# CC2753 register map
File version: 1.0
CPU: CM0+ r0p4, little endian, no MPU, no FPU, VTOR, 3 interrupt priority bits
Registers are 32-bit, read-write, reset 0x0 unless marked. A register's access mark holds for its fields unless they carry their own. Offsets are from the block's base; [hi:lo] are bit positions; {n}, {i} and the like mark numbered series; 'fields as' and 'values as' point back to an identical list.

## HSMCRYPTO — HSM is a Root of Trust Engine that protects valuable assets, such as secret keys for embedded security sensitive applications in a Trusted Execution Environment
Base 0x400F0000
0x00 MB1IN ro — Input Mailbox 1
  [31:0] MEM — Input Mailbox Memory
0x00 MB1OUT wo — Output Mailbox 1
  [31:0] MEM — Output Mailbox Memory
0x400 MB2IN ro — Input Mailbox 2
  [31:0] MEM — Input Mailbox Memory
0x400 MB2OUT wo — Output Mailbox 2
  [31:0] MEM — Output Mailbox Memory
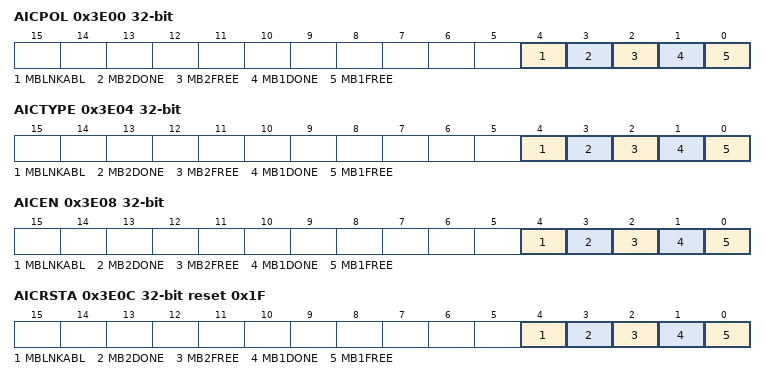
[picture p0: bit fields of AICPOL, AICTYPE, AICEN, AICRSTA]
0x3E00 AICPOL — AIC Polarity Control Register
  [all] fields
    1=HIGHRISE (High level/rising edge); 0=LOWFALL (Low level/falling edge)
  [4] MBLNKABL — Mailbox Linkable Interrupt Polarity
  [3] MB2DONE — Mailbox 2 Token Done Interrupt Polarity
  [2] MB2FREE — Mailbox 2 Free Interrupt Polarity
  [1] MB1DONE — Mailbox 1 Token done Interrupt Polarity
  [0] MB1FREE — Mailbox 1 Free Interrupt Polarity
0x3E04 AICTYPE — AIC Type Control Register
  [4] MBLNKABL — Mailbox Linkable Interrupt Type
    1=EDG (Edge); 0=LVL (Level)
  [3] MB2DONE — Mailbox 2 Token Done Interrupt Type
    1=EDG (Edge); 0=LEVEL
  [2] MB2FREE — Mailbox 2 Free Interrupt Type
    1=EDG (Edge); 0=LVL (Level)
  [1] MB1DONE — Mailbox 1 Token Done Interrupt Type
    1=EDG (Edge); 0=LVL (Level)
  [0] MB1FREE — Mailbox 1 Free Interrupt Type
    1=EDG (Edge); 0=LVL (Level)
0x3E08 AICEN — AIC Enable Control Register
  [all] fields
    1=EN (Enable); 0=DIS (Disable)
  [4] MBLNKABL — Mailbox Linkable Interrupt Enable. Indicates one or more mailbox can be linked
  [3] MB2DONE — Mailbox 2 Token Done Interrupt Enable
  [2] MB2FREE — Mailbox 2 Free Interrupt Enable
  [1] MB1DONE — Mailbox 1 Token done Interrupt Enable
  [0] MB1FREE — Mailbox 1 Free Interrupt Enable
0x3E0C AICRSTA ro reset 0x1F — AIC Raw Source Status Register
  [4] MBLNKABL — Mailbox Linkable Interrupt Status. Indicates one or more mailbox can be linked
  [3] MB2DONE — Mailbox 2 Token Done Interrupt Status
  [2] MB2FREE — Mailbox 2 Free Interrupt Status
  [1] MB1DONE — Mailbox 1 Token done Interrupt Status
  [0] MB1FREE — Mailbox 1 Free Interrupt Status
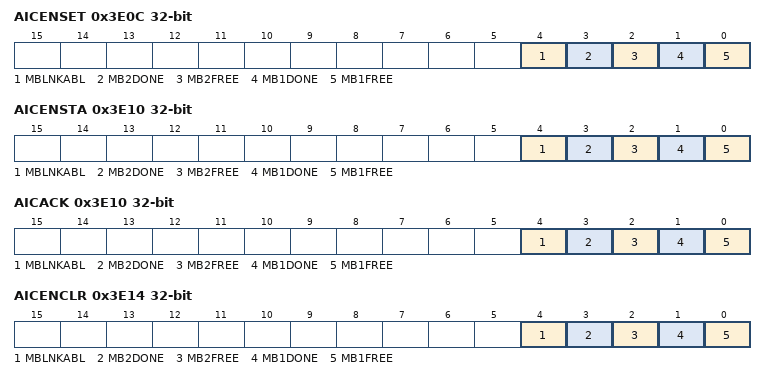
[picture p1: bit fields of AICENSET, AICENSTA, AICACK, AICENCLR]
0x3E0C AICENSET wo — AIC Enable Set Registers
  [all] fields
    1=SET (Set Enable)
  [4] MBLNKABL — Mailbox Linkable Interrupt Enable Set
  [3] MB2DONE — MailBox 2 Token Done Interrupt Enable Set
  [2] MB2FREE — MailBox 2 Free Interrupt Enable Set
  [1] MB1DONE — MailBox 1 Token Done Interrupt Enable Set
  [0] MB1FREE — MailBox 1 Free Interrupt Enable Set
0x3E10 AICENSTA ro — AIC Enabled Status Register
  [4] MBLNKABL — Mailbox Linkable Interrupt Enable Status
  [3] MB2DONE — Mailbox 2 Done Interrupt Enable Status
  [2] MB2FREE — MailBox 2 Free Interrupt Enable Status
  [1] MB1DONE — MailBox 1 Token Done Interrupt Enable Status
  [0] MB1FREE — Mailbox 1 Free Interrupt Enable Status
0x3E10 AICACK wo — AIC Acknowledge Register
  [all] fields
    1=ACK (Interrupt Ack)
  [4] MBLNKABL — Mailbox Linkable Interrupt Acknowledge
  [3] MB2DONE — Mailbox 2 Done Interrupt Acknowledge
  [2] MB2FREE — MailBox 2 Free Interrupt Acknowledge
  [1] MB1DONE — MailBox 1 Token Done Interrupt Acknowledge
  [0] MB1FREE — Mailbox 1 Free Interrupt Acknowledge
0x3E14 AICENCLR wo — AIC Enable Clear Register
  [all] fields
    1=CLR (Clear Enable)
  [4] MBLNKABL — Mailbox Linkable Interrupt Enable Clear
  [3] MB2DONE — Mailbox 2 Done Interrupt Enable Clear
  [2] MB2FREE — MailBox 2 Free Interrupt Enable Clear
  [1] MB1DONE — MailBox 1 Token Done Interrupt Enable Clear
  [0] MB1FREE — Mailbox 1 Free Interrupt Enable Clear
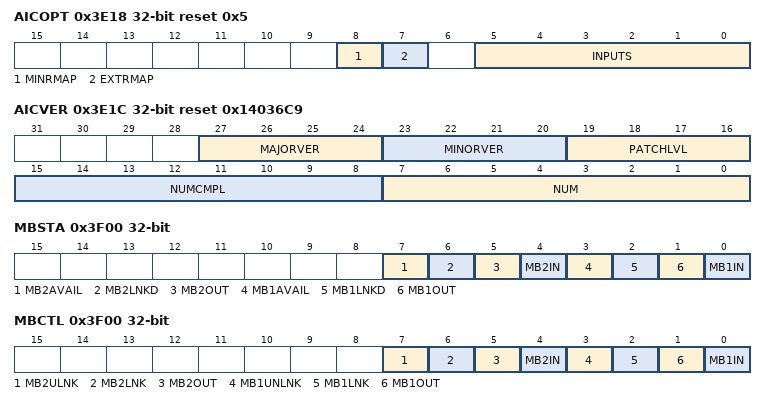
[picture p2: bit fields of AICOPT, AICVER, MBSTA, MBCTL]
0x3E18 AICOPT ro reset 0x5 — AIC Options Register
  [8] MINRMAP — Mini register map.
  [7] EXTRMAP — Extended register map.
  [5:0] INPUTS — The number of interrupt request inputs.
0x3E1C AICVER ro reset 0x14036C9 — AIC Version Register
  [27:24] MAJORVER — These bits encode the major version number for the AIC module.
  [23:20] MINORVER — These bits encode the minor version number for the AIC module.
  [19:16] PATCHLVL — These bits encode the hardware patch level for the AIC module, starting at value 0 on the first release.
  [15:8] NUMCMPL — These bits simply contain the complement of bits [7:0], used by a driver to ascertain that this version register is indeed read.
  [7:0] NUM — These bits encode the AIC number.
0x3F00 MBSTA ro — Mailbox Status Register
  [7] MB2AVAIL — Input Mailbox 2 available status
    1=AVAIL (Input Mailbox is available for linking by this Host); 0=NAVAIL (Input Mailbox is linked to a Host or is filled)
  [6] MB2LNKD — Mailbox 2 Link Status
    1=LNKD (This Host is linked to Mailbox); 0=NLNKD (This Host is not linked to Mailbox)
  [5] MB2OUT — Output Mailbox 2 Status
    1=FULL (Mailbox is Full); 0=EMTY (Mailbox is Empty)
  [4] MB2IN — Input Mailbox 2 Status
    1=FULL (Mailbox is Full); 0=EMTY (Mailbox is Empty)
  [3] MB1AVAIL — Input Mailbox 1 available status
    values as MB2AVAIL
  [2] MB1LNKD — Mailbox 1 Link Status
    values as MB2LNKD
  [1] MB1OUT — Output Mailbox 1 Status
    1=FULL (Mailbox is Full); 0=EMTY (Mailbox is Empty)
  [0] MB1IN — Input Mailbox 1 Status
    1=FULL (Mailbox is Full); 0=EMTY (Mailbox is Empty)
0x3F00 MBCTL wo — Mailbox Control Register
  [7] MB2ULNK — Unlink the Mailbox from this host
    1=UNLNK (unlink Mailbox 2)
  [6] MB2LNK — Link Mailbox to this Host. Host can link to a mailbox only if it is not filled and not linked to another host
    1=LNK (Link Mailbox 2)
  [5] MB2OUT — The Host for whom the token is in Output Mailbox 1 can clear the status
    1=EMTY (Set output mailbox empty)
  [4] MB2IN — The Host linked to input mailbox 2 can set after placing a token into Input Mailbox 2
    1=FULL (Set Input Mailbox full)
  [3] MB1UNLNK — Unlink the Mailbox from this host
    1=UNLNK (Unlink Mailbox 1)
  [2] MB1LNK — Link Mailbox to this Host. Host can link to a mailbox only if it is not filled and not linked to another host
    1=LNK (Link Mailbox 1)
  [1] MB1OUT — The Host for whom the token is in Output Mailbox 1 can clear the status
    1=EMTY (Set output mailbox empty)
  [0] MB1IN — The Host linked to input mailbox 1 can set after placing a token into Input Mailbox 1
    1=FULL (Set Input Mailbox full)
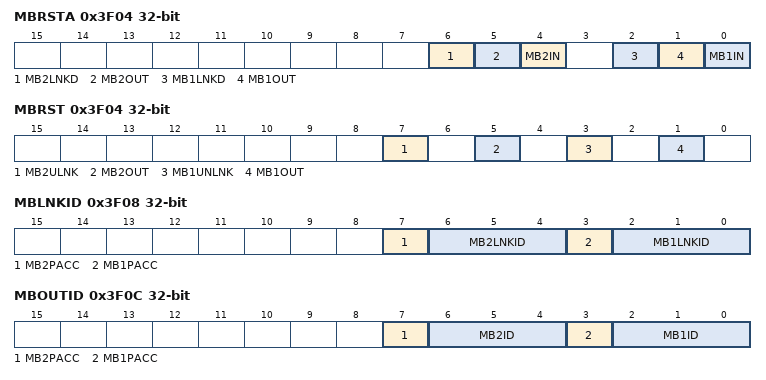
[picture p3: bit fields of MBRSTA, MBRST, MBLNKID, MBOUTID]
0x3F04 MBRSTA ro — Raw Mailbox Status Register
  [6] MB2LNKD — Mailbox 2 Linked Raw Status
    values as MBSTA.MB2LNKD
  [5] MB2OUT — Output Mailbox 2 Raw Status
    1=FULL (Mailbox is Full); 0=EMTY (Mailbox is Empty)
  [4] MB2IN — Input Mailbox 2 Raw Status
    1=FULL (Mailbox is Full); 0=EMTY (Mailbox is Empty)
  [2] MB1LNKD — Mailbox 1 Linked Raw Status
    values as MBSTA.MB2LNKD
  [1] MB1OUT — Output Mailbox 1 Raw Status
    1=FULL (Mailbox is Full); 0=EMTY (Mailbox is Empty)
  [0] MB1IN — Input Mailbox 1 Raw Status
    1=FULL (Mailbox is Full); 0=EMTY (Mailbox is Empty)
0x3F04 MBRST wo — Mailbox Reset Register. Only Master Host can write into this register
  [7] MB2ULNK — Set only - Master Host can unlink mbx from current Host by writing 1b here.
    1=UNLNK (Unlink Mailbox)
  [5] MB2OUT — Set only - Master Host can clear mbx_out_full bit in MBSTA by writing 1b here.
    1=EMTY (Set Mailbox Empty)
  [3] MB1UNLNK — Set only - Master Host can unlink mbx from current Host by writing 1b here.
    1=UNLNK (Unlink Mailbox)
  [1] MB1OUT — Set only - Master Host can clear mbx_out_full bit in MBSTA by writing 1b here.
    1=EMTY (Set Mailbox Empty)
0x3F08 MBLNKID ro — Mailbox Status - linked Host IDs Register
  [7] MB2PACC — 0: Mailbox 2 can be accessed by the Host using protected or non-protected access. 1: Mailbox 2 is only accessible if the Host uses protected access.
  [6:4] MB2LNKID — Host cpu_id of the Host linked to the Mailbox 2
  [3] MB1PACC — 0: Mailbox 1 can be accessed by the Host using protected or non-protected access. 1: Mailbox 1 is only accessible if the Host uses protected access.
  [2:0] MB1LNKID — Host cpu_id of the Host linked to the Mailbox 1
0x3F0C MBOUTID ro — Mailbox Status - output Host IDs Register
  [7] MB2PACC — 0: Output mailbox 2 can be accessed by the Host using protected or non-protected access. 1: Output mailbox 2 is only accessible if the Host uses protected access.
  [6:4] MB2ID — Host cpu_id of the Host allowed to read a result from the Mailbox 2
  [3] MB1PACC — 0: Output mailbox 1 can be accessed by the Host using protected or non-protected access. 1: Output mailbox 1 is only accessible if the Host uses protected access.
  [2:0] MB1ID — HostID of the Host allowed to read a result from the Mailbox 1
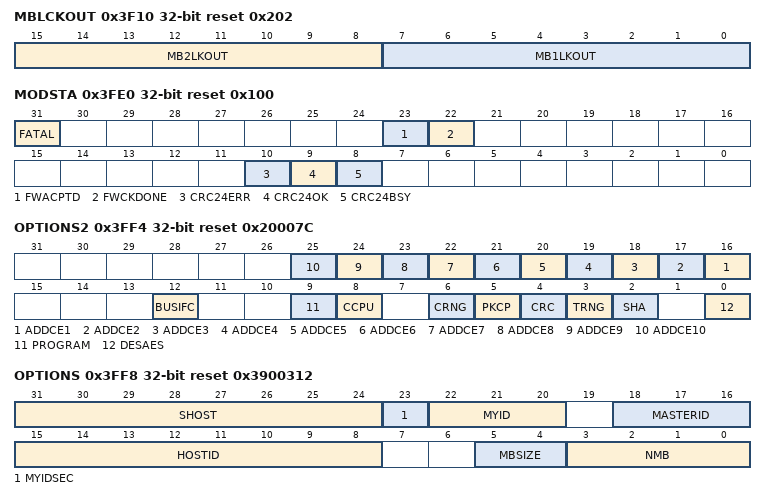
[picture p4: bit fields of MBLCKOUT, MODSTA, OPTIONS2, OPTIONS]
0x3F10 MBLCKOUT reset 0x202 — Host or Mailbox lockout control Register
  [15:8] MB2LKOUT — Bit map indicates which Hosts are blocked from accessing mailbox 2
  [7:0] MB1LKOUT — Bit map indicates which Hosts are blocked from accessing mailbox 1
0x3FE0 MODSTA reset 0x100 — Module Status Register
  [31] FATAL ro — Set if fatal error occured
  [23] FWACPTD ro — Set if firmware is to be executed
  [22] FWCKDONE ro — Set if firmware checks complete
  [10] CRC24ERR ro — Set if CRC on ProgramROM is fails
  [9] CRC24OK ro — Set if CRC on ProgramROM is passes
  [8] CRC24BSY ro — Set if CRC on ProgramROM is busy
0x3FF4 OPTIONS2 ro reset 0x20007C — Configured options(2)
  [n+15] ADDCE{n} (n=1..10) — An additional crypto engine is available in hardware as custom engine{n}
  [12] BUSIFC — Bus interface type, 0b = 32-bit AHB, 1b = 32-bit AXI
  [9] PROGRAM — Downloadable RAM based firmware program memory.
  [8] CCPU — C capable local cpu available
  [6] CRNG — CRNG engine available
  [5] PKCP — PKCP Engine available
  [4] CRC — CRC calculation available
  [3] TRNG — TRNG engine available
  [2] SHA — SHA1/SHA2 combination core available
  [0] DESAES — DES/AES combination crypto core available
0x3FF8 OPTIONS ro reset 0x3900312 — Configured options(1)
  [31:24] SHOST — Bits to indicate which of the 8 possible HOSTID codes on the bus interface are active Hosts with secure access
  [23] MYIDSEC — Indicates the current protection bit values of the Host actually reading the register
  [22:20] MYID — Host ID code for the Host that is reading this register
  [18:16] MASTERID — Value of the HOSTID that designates the Master Host
  [15:8] HOSTID — Bits to indicate which of the 8 possible HOSTID codes on the bus interface are active
  [5:4] MBSIZE — Mailbox pair Size
    3=MB1024 (1024 Bytes); 2=MB512 (512 Bytes); 1=MB256 (256 Bytes); 0=MB128 (128 Bytes)
  [3:0] NMB — Number of Input/Output Mailbox pairs
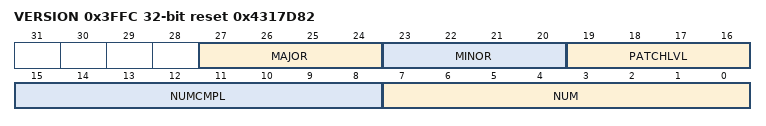
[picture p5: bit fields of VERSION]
0x3FFC VERSION ro reset 0x4317D82
  [27:24] MAJOR — Major Version release number for this module
  [23:20] MINOR — Minor Version release number for this module
  [19:16] PATCHLVL — Hardware Patch Level for this module
  [15:8] NUMCMPL — Bit by Bit compliment of IP Number
  [7:0] NUM — IP number
